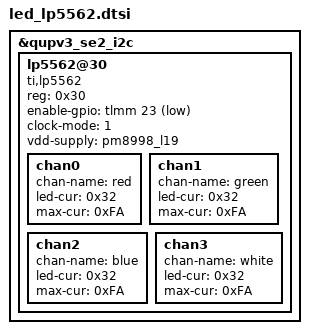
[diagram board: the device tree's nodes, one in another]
/*
   LED IC - LP5562
*/
&qupv3_se2_i2c {
	status = "okay";

	lp5562@30 {
                        compatible = "ti,lp5562";
                        reg = <0x30>;
                        enable-gpio = <&tlmm 23 0x1>;
                        clock-mode = /bits/8 <1>;
                        vdd-supply = <&pm8998_l19>; //3.3V

                        chan0 {
                                chan-name = "red";
                                led-cur = /bits/ 8 <0x32>; /* 5mA */
                                max-cur = /bits/ 8 <0xFA>; /* 25mA */
                        };

                        chan1 {
                                chan-name = "green";
                                led-cur = /bits/ 8 <0x32>; /* 5mA */
                                max-cur = /bits/ 8 <0xFA>; /* 25mA */
                        };

                        chan2 {
                                chan-name = "blue";
                                led-cur = /bits/ 8 <0x32>; /* 5mA */
                                max-cur = /bits/ 8 <0xFA>; /* 25mA */
                        };

                        chan3 {
                                chan-name = "white";
                                led-cur = /bits/ 8 <0x32>; /* 5mA */
                                max-cur = /bits/ 8 <0xFA>; /* 25mA */
                        };
                };

};
